# ADC_SAFETY_ADC_SAFETY_AGGR_502CEC00h register map
Vendor: Texas Instruments
Peripheral module from a debugger description file (folder AM263P).
Registers are 32-bit, read-write, reset 0x0 unless marked. A register's access mark holds for its fields unless they carry their own. Offsets are as the file gives them; lines under a group give offsets from that group; [hi:lo] are bit positions; {n}, {i} and the like mark numbered series; 'fields as' and 'values as' point back to an identical list; <NAME> marks a mode.

## ADC_SAFETY_AGGR
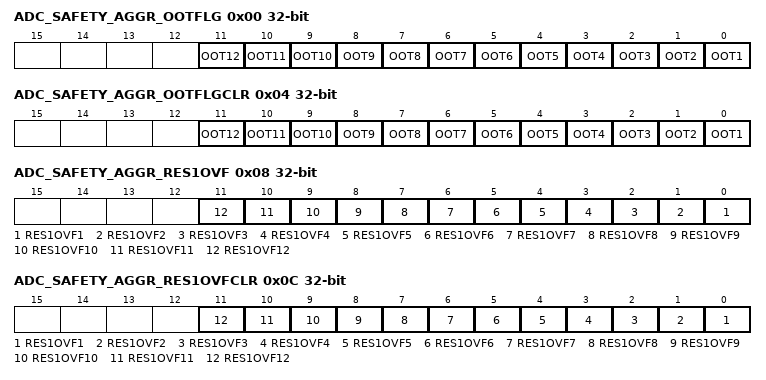
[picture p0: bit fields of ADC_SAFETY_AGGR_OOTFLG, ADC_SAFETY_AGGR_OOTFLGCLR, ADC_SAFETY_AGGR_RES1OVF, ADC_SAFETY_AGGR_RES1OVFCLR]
0x00 ADC_SAFETY_AGGR_OOTFLG ro — Checker Out-of-Tolerance Flag Register.
  [11] OOT12 — ADC results safety checker 12 out-of-tolerance flag. Set when CHECK12 detects a difference between configured conversion results greater than the configured tolerance. Use the CHECKINTSEL1, CHECKINTSEL2, CHECKINTSEL3, CHECKEVTxSEL1, CHECKEVTxSEL2, and CHECKEVTxSEL3 registers to aggregate detected OOT and OVF flags into interrupt [INT] or X-bar events [EVT].
  [10] OOT11 — ADC results safety checker 11 out-of-tolerance flag. Set when CHECK11 detects a difference between configured conversion results greater than the configured tolerance. Use the CHECKINTSEL1, CHECKINTSEL2, CHECKINTSEL3, CHECKEVTxSEL1, CHECKEVTxSEL2, and CHECKEVTxSEL3 registers to aggregate detected OOT and OVF flags into interrupt [INT] or X-bar events [EVT].
  [9] OOT10 — ADC results safety checker 10 out-of-tolerance flag. Set when CHECK10 detects a difference between configured conversion results greater than the configured tolerance. Use the CHECKINTSEL1, CHECKINTSEL2, CHECKINTSEL3, CHECKEVTxSEL1, CHECKEVTxSEL2, and CHECKEVTxSEL3 registers to aggregate detected OOT and OVF flags into interrupt [INT] or X-bar events [EVT].
  [8] OOT9 — ADC results safety checker 1 out-of-tolerance flag. Set when CHECK9 detects a difference between configured conversion results greater than the configured tolerance. Use the CHECKINTSEL1, CHECKINTSEL2, CHECKINTSEL3, CHECKEVTxSEL1, CHECKEVTxSEL2, and CHECKEVTxSEL3 registers to aggregate detected OOT and OVF flags into interrupt [INT] or X-bar events [EVT].
  [n-1] OOT{n} (n=1..8) — ADC results safety checker {n} out-of-tolerance flag. Set when CHECK{n} detects a difference between configured conversion results greater than the configured tolerance. Use the CHECKINTSEL1, CHECKINTSEL2, CHECKINTSEL3, CHECKEVTxSEL1, CHECKEVTxSEL2, and CHECKEVTxSEL3 registers to aggregate detected OOT and OVF flags into interrupt [INT] or X-bar events [EVT].
0x04 ADC_SAFETY_AGGR_OOTFLGCLR access not given — Checker Out-of-Tolerance Flag Clear Register.
  [n-1] OOT{n} (n=1..12) — ADC results safety checker {n} out-of-tolerance flag clear. Used to clear OOT status from CHECK{n}. In the case of a safety checker interrupt, clear all serviced OOT or OVF flags first, then clear the global interrupt flag [in the CHKINTFLG register] using the CHKINTFLGCLR register. In the case of a safety checker X-bar event, clear all associated OOT or OVF flags to clear the event. (access R/W1TS)
0x08 ADC_SAFETY_AGGR_RES1OVF ro — Checker Overflow Result 1 Flag Register.
  [n-1] RES1OVF{n} (n=1..12) — ADC results safety checker {n} overflow flag for result 1. Set when CHECK{n} detects that conversion result 1 has arrived more than once before result 2 has arrived. Use the CHECKINTSEL1, CHECKINTSEL2, CHECKINTSEL3, CHECKEVTxSEL1, CHECKEVTxSEL2, and CHECKEVTxSEL3 registers to aggregate detected OOT and OVF flags into interrupt [INT] or X-bar events [EVT].
0x0C ADC_SAFETY_AGGR_RES1OVFCLR access not given — Checker Overflow Result 1 Flag Clear Register.
  [n-1] RES1OVF{n} (n=1..12) — ADC results safety checker {n} result 1 overflow flag clear. Used to clear RES1OVF status from CHECK{n}. In the case of a safety checker interrupt, clear all serviced OOT or OVF flags first, then clear the global interrupt flag [in the CHECKINTFLG register] using the CHKINTFLGCLR register. In the case of a safety checker X-bar event, clear all associated OOT or OVF flags to clear the event. (access R/W1TS)
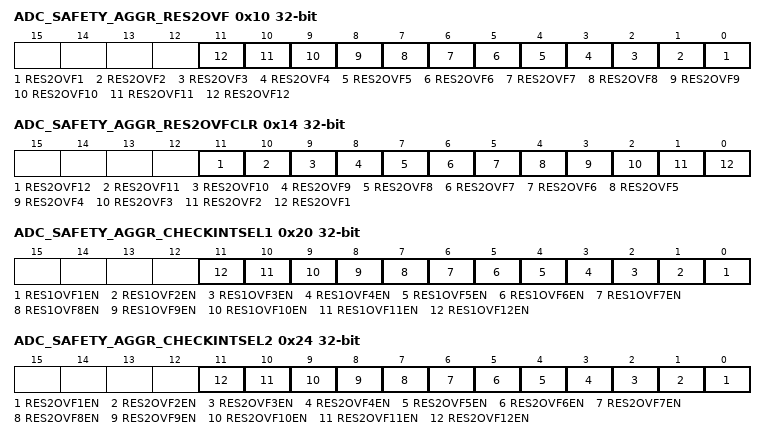
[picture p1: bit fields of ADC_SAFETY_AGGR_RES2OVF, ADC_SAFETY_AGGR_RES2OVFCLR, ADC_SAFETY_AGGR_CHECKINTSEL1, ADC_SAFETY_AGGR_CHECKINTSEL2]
0x10 ADC_SAFETY_AGGR_RES2OVF ro — Checker Overflow Result 2 Flag Register.
  [n-1] RES2OVF{n} (n=1..12) — ADC results safety checker {n} overflow flag for result 2. Set when CHECK{n} detects that conversion result 2 has arrived more than once before result 1 has arrived. Use the CHECKINTSEL1, CHECKINTSEL2, CHECKINTSEL3, CHECKEVTxSEL1, CHECKEVTxSEL2, and CHECKEVTxSEL3 registers to aggregate detected OOT and OVF flags into interrupt [INT] or X-bar events [EVT].
0x14 ADC_SAFETY_AGGR_RES2OVFCLR access not given — Checker Overflow Result 2 Flag Clear Register.
  [11] RES2OVF12 — ADC results safety checker 12 result overflow flag clear. Used to clear OVF status from CHECK12. In the case of a safety checker interrupt, clear all serviced OOT or OVF flags first, then clear the global interrupt flag [in the CHECKINTFLG register] using the CHECKINTFLGCLR register. In the case of a safety checker X-bar event, clear all associated OOT or OVF flags to clear the event. (access R/W1TS)
  [10] RES2OVF11 — ADC results safety checker 11 result overflow flag clear. Used to clear OVF status from CHECK11. In the case of a safety checker interrupt, clear all serviced OOT or OVF flags first, then clear the global interrupt flag [in the CHECKINTFLG register] using the CHECKINTFLGCLR register. In the case of a safety checker X-bar event, clear all associated OOT or OVF flags to clear the event. (access R/W1TS)
  [9] RES2OVF10 — ADC results safety checker 10 result overflow flag clear. Used to clear OVF status from CHECK10. In the case of a safety checker interrupt, clear all serviced OOT or OVF flags first, then clear the global interrupt flag [in the CHECKINTFLG register] using the CHECKINTFLGCLR register. In the case of a safety checker X-bar event, clear all associated OOT or OVF flags to clear the event. (access R/W1TS)
  [8] RES2OVF9 — ADC results safety checker 9 result overflow flag clear. Used to clear OVF status from CHECK9. In the case of a safety checker interrupt, clear all serviced OOT or OVF flags first, then clear the global interrupt flag [in the CHECKINTFLG register] using the CHKINTFLGCLR register. In the case of a safety checker X-bar event, clear all associated OOT or OVF flags to clear the event. (access R/W1TS)
  [7] RES2OVF8 — ADC results safety checker 8 result overflow flag clear. Used to clear OVF status from CHECK8. In the case of a safety checker interrupt, clear all serviced OOT or OVF flags first, then clear the global interrupt flag [in the CHECKINTFLG register] using the CHECKINTFLGCLR register. In the case of a safety checker X-bar event, clear all associated OOT or OVF flags to clear the event. (access R/W1TS)
  [6] RES2OVF7 — ADC results safety checker 7 result overflow flag clear. Used to clear OVF status from CHECK7. In the case of a safety checker interrupt, clear all serviced OOT or OVF flags first, then clear the global interrupt flag [in the CHECKINTFLG register] using the CHECKINTFLGCLR register. In the case of a safety checker X-bar event, clear all associated OOT or OVF flags to clear the event. (access R/W1TS)
  [5] RES2OVF6 — ADC results safety checker 6 result overflow flag clear. Used to clear OVF status from CHECK6. In the case of a safety checker interrupt, clear all serviced OOT or OVF flags first, then clear the global interrupt flag [in the CHECKINTFLG register] using the CHECKINTFLGCLR register. In the case of a safety checker X-bar event, clear all associated OOT or OVF flags to clear the event. (access R/W1TS)
  [4] RES2OVF5 — ADC results safety checker 5 result overflow flag clear. Used to clear OVF status from CHECK5. In the case of a safety checker interrupt, clear all serviced OOT or OVF flags first, then clear the global interrupt flag [in the CHECKINTFLG register] using the CHKINTFLGCLR register. In the case of a safety checker X-bar event, clear all associated OOT or OVF flags to clear the event. (access R/W1TS)
  [3] RES2OVF4 — ADC results safety checker 4 result overflow flag clear. Used to clear OVF status from CHECK4. In the case of a safety checker interrupt, clear all serviced OOT or OVF flags first, then clear the global interrupt flag [in the CHECKINTFLG register] using the CHECKINTFLGCLR register. In the case of a safety checker X-bar event, clear all associated OOT or OVF flags to clear the event. (access R/W1TS)
  [2] RES2OVF3 — ADC results safety checker 3 result overflow flag clear. Used to clear OVF status from CHECK3. In the case of a safety checker interrupt, clear all serviced OOT or OVF flags first, then clear the global interrupt flag [in the CHECKINTFLG register] using the CHECKINTFLGCLR register. In the case of a safety checker X-bar event, clear all associated OOT or OVF flags to clear the event. (access R/W1TS)
  [1] RES2OVF2 — ADC results safety checker 2 result overflow flag clear. Used to clear OVF status from CHECK2. In the case of a safety checker interrupt, clear all serviced OOT or OVF flags first, then clear the global interrupt flag [in the CHECKINTFLG register] using the CHECKINTFLGCLR register. In the case of a safety checker X-bar event, clear all associated OOT or OVF flags to clear the event. (access R/W1TS)
  [0] RES2OVF1 — ADC results safety checker 1 result overflow flag clear. Used to clear OVF status from CHECK1. In the case of a safety checker interrupt, clear all serviced OOT or OVF flags first, then clear the global interrupt flag [in the CHECKINTFLG register] using the CHKINTFLGCLR register. In the case of a safety checker X-bar event, clear all associated OOT or OVF flags to clear the event. (access R/W1TS)
0x18 ADC_SAFETY_AGGR_CHECKINTFLG 16-bit ro — Checker Interrupt Flag Register.
  [0] CHECKINT — ADC results safety checker subsytem interrupt flag. Indicates that one or more configured OOT or OVF conditions have occurred in the individual safety checker modules. In the ISR, clear all serviced OOT or OVF flags first [using the OOTFLGCLR and OVFFLGCLR registers], then clear this flag using the CHKINTFLGCLR register. The CHECKINTSEL1 and CHECKINTSEL2 registers are used to select which OOT and OVF flags from the individual checker modules can trigger this interrupt.
0x1C ADC_SAFETY_AGGR_CHECKINTFLGCLR 16-bit access not given — Checker Interrupt Flag Clear Register.
  [0] CHECKINTCLR — ADC results safety checker subsytem interrupt flag clear. Used to clear the global safety checker subsystem interrupt flag. In the ISR, clear all serviced OOT or OVF flags first [using the OOTFLGCLR and OVFFLGCLR registers], then clear the global CHECKINT flag using the this register. (access R/W1TS)
0x20 ADC_SAFETY_AGGR_CHECKINTSEL1 — Checker Interrupt Source Select Register 1
  [n-1] RES1OVF{n}EN (n=1..12) — Enable CHECK{n} RES1OVF as a source for CHECKINT.
0x24 ADC_SAFETY_AGGR_CHECKINTSEL2 — Checker Interrupt Source Select Register 2
  [n-1] RES2OVF{n}EN (n=1..12) — Enable CHECK{n} RES2OVF as a source for CHECKINT.
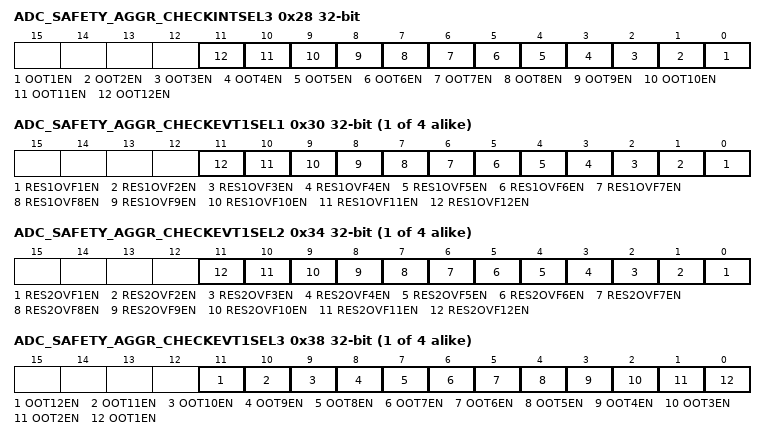
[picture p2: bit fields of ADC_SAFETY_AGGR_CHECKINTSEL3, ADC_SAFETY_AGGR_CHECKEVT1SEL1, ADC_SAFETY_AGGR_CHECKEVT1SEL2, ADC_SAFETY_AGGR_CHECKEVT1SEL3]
0x28 ADC_SAFETY_AGGR_CHECKINTSEL3 — Checker Interrupt Source Select Register 3
  [n-1] OOT{n}EN (n=1..12) — Enable CHECK{n} OOT as a source for CHECKINT.
{0x20+0x10*i} ADC_SAFETY_AGGR_CHECKEVT{i}SEL1 (i=1..4) — Checker X-Bar EVT{i} Source Select Register 1
  [n-1] RES1OVF{n}EN (n=1..12) — Enable CHECK{n} RES1OVF as a source for CHECKEVT{i}.
{0x24+0x10*i} ADC_SAFETY_AGGR_CHECKEVT{i}SEL2 (i=1..4) — Checker X-Bar EVT{i} Source Select Register 2
  [n-1] RES2OVF{n}EN (n=1..12) — Enable CHECK{n} RES2OVF as a source for CHECKEVT{i}.
{0x28+0x10*i} ADC_SAFETY_AGGR_CHECKEVT{i}SEL3 (i=1..4) — Checker X-Bar EVT{i} Source Select Register 3
  [11] OOT12EN — Enable CHECK12 OOT as a source for CHECKEVT{i}.
  [10] OOT11EN — Enable CHECK11 OOTas a source for CHECKEVT{i}.
  [9] OOT10EN — Enable CHECK10 OOT as a source for CHECKEVT{i}.
  [8] OOT9EN — Enable CHECK9 OOT as a source for CHECKEVT{i}.
  [7] OOT8EN — Enable CHECK8 OOT as a source for CHECKEVT{i}.
  [6] OOT7EN — Enable CHECK7 OOTas a source for CHECKEVT{i}.
  [5] OOT6EN — Enable CHECK6 OOT as a source for CHECKEVT{i}.
  [4] OOT5EN — Enable CHECK5 OOT as a source for CHECKEVT{i}.
  [3] OOT4EN — Enable CHECK4 OOT as a source for CHECKEVT{i}.
  [2] OOT3EN — Enable CHECK3 OOTas a source for CHECKEVT{i}.
  [1] OOT2EN — Enable CHECK2 OOT as a source for CHECKEVT{i}.
  [0] OOT1EN — Enable CHECK1 OOT as a source for CHECKEVT{i}.
